AUTOSAR XML (schema 3.1.2)
package /Components/SWC_EngLimTqT
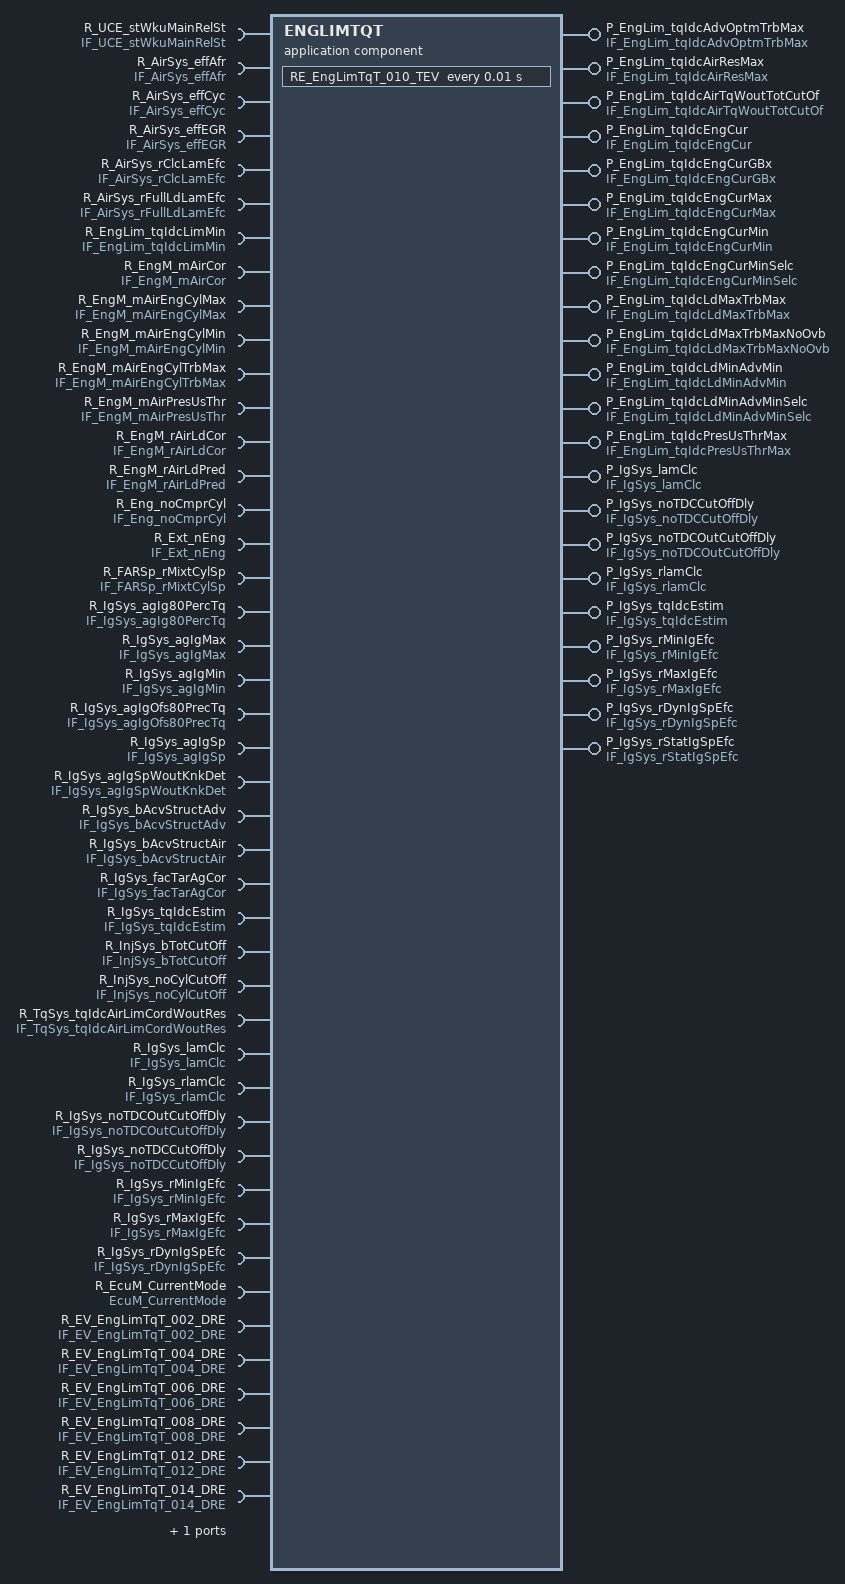
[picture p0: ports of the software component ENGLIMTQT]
  application software component type ENGLIMTQT  # EngLimTqT
    require port R_UCE_stWkuMainRelSt: required-interface=IF_UCE_stWkuMainRelSt
    22 x provide port:
      P_EngLim_tqIdcAdvOptmTrbMax: unqueued-sender-com-spec{data-element=EngLim_tqIdcAdvOptmTrbMax, can-invalidate=false, init-value=ConstantValue}, provided-interface=IF_EngLim_tqIdcAdvOptmTrbMax
      P_EngLim_tqIdcAirResMax: unqueued-sender-com-spec{data-element=EngLim_tqIdcAirResMax, can-invalidate=false, init-value=ConstantValue1}, provided-interface=IF_EngLim_tqIdcAirResMax
      P_EngLim_tqIdcAirTqWoutTotCutOf: unqueued-sender-com-spec{data-element=EngLim_tqIdcAirTqWoutTotCutOf, can-invalidate=false, init-value=ConstantValue3}, provided-interface=IF_EngLim_tqIdcAirTqWoutTotCutOf
      P_EngLim_tqIdcEngCur: unqueued-sender-com-spec{data-element=EngLim_tqIdcEngCur, can-invalidate=false, init-value=ConstantValue5}, provided-interface=IF_EngLim_tqIdcEngCur
      P_EngLim_tqIdcEngCurGBx: unqueued-sender-com-spec{data-element=EngLim_tqIdcEngCurGBx, can-invalidate=false, init-value=ConstantValue7}, provided-interface=IF_EngLim_tqIdcEngCurGBx
      P_EngLim_tqIdcEngCurMax: unqueued-sender-com-spec{data-element=EngLim_tqIdcEngCurMax, can-invalidate=false, init-value=ConstantValue9}, provided-interface=IF_EngLim_tqIdcEngCurMax
      P_EngLim_tqIdcEngCurMin: unqueued-sender-com-spec{data-element=EngLim_tqIdcEngCurMin, can-invalidate=false, init-value=ConstantValue11}, provided-interface=IF_EngLim_tqIdcEngCurMin
      P_EngLim_tqIdcEngCurMinSelc: unqueued-sender-com-spec{data-element=EngLim_tqIdcEngCurMinSelc, can-invalidate=false, init-value=ConstantValue13}, provided-interface=IF_EngLim_tqIdcEngCurMinSelc
      P_EngLim_tqIdcLdMaxTrbMax: unqueued-sender-com-spec{data-element=EngLim_tqIdcLdMaxTrbMax, can-invalidate=false, init-value=ConstantValue15}, provided-interface=IF_EngLim_tqIdcLdMaxTrbMax
      P_EngLim_tqIdcLdMaxTrbMaxNoOvb: unqueued-sender-com-spec{data-element=EngLim_tqIdcLdMaxTrbMaxNoOvb, can-invalidate=false, init-value=ConstantValue17}, provided-interface=IF_EngLim_tqIdcLdMaxTrbMaxNoOvb
      P_EngLim_tqIdcLdMinAdvMin: unqueued-sender-com-spec{data-element=EngLim_tqIdcLdMinAdvMin, can-invalidate=false, init-value=ConstantValue19}, provided-interface=IF_EngLim_tqIdcLdMinAdvMin
      P_EngLim_tqIdcLdMinAdvMinSelc: unqueued-sender-com-spec{data-element=EngLim_tqIdcLdMinAdvMinSelc, can-invalidate=false, init-value=ConstantValue21}, provided-interface=IF_EngLim_tqIdcLdMinAdvMinSelc
      P_EngLim_tqIdcPresUsThrMax: unqueued-sender-com-spec{data-element=EngLim_tqIdcPresUsThrMax, can-invalidate=false, init-value=ConstantValue23}, provided-interface=IF_EngLim_tqIdcPresUsThrMax
      P_IgSys_lamClc: unqueued-sender-com-spec{data-element=IgSys_lamClc, can-invalidate=false, init-value=UInt32InitValue}, provided-interface=IF_IgSys_lamClc
      P_IgSys_noTDCCutOffDly: unqueued-sender-com-spec{data-element=IgSys_noTDCCutOffDly, can-invalidate=false, init-value=ConstantValue25}, provided-interface=IF_IgSys_noTDCCutOffDly
      P_IgSys_noTDCOutCutOffDly: unqueued-sender-com-spec{data-element=IgSys_noTDCOutCutOffDly, can-invalidate=false, init-value=ConstantValue27}, provided-interface=IF_IgSys_noTDCOutCutOffDly
      P_IgSys_rlamClc: unqueued-sender-com-spec{data-element=IgSys_rlamClc, can-invalidate=false, init-value=ConstantValue29}, provided-interface=IF_IgSys_rlamClc
      P_IgSys_tqIdcEstim: unqueued-sender-com-spec{data-element=IgSys_tqIdcEstim, can-invalidate=false, init-value=SInt16InitValue}, provided-interface=IF_IgSys_tqIdcEstim
      P_IgSys_rMinIgEfc: unqueued-sender-com-spec{data-element=IgSys_rMinIgEfc, can-invalidate=false, init-value=UInt16InitValue}, provided-interface=IF_IgSys_rMinIgEfc
      P_IgSys_rMaxIgEfc: unqueued-sender-com-spec{data-element=IgSys_rMaxIgEfc, can-invalidate=false, init-value=UInt16InitValue31}, provided-interface=IF_IgSys_rMaxIgEfc
      P_IgSys_rDynIgSpEfc: unqueued-sender-com-spec{data-element=IgSys_rDynIgSpEfc, can-invalidate=false, init-value=UInt16InitValue33}, provided-interface=IF_IgSys_rDynIgSpEfc
      P_IgSys_rStatIgSpEfc: unqueued-sender-com-spec{data-element=IgSys_rStatIgSpEfc, can-invalidate=false, init-value=UInt16InitValue35}, provided-interface=IF_IgSys_rStatIgSpEfc
    44 x require port:
      R_AirSys_effAfr: unqueued-receiver-com-spec{data-element=AirSys_effAfr, init-value=ConstantValue37, resync-time=0}, required-interface=IF_AirSys_effAfr
      R_AirSys_effCyc: unqueued-receiver-com-spec{data-element=AirSys_effCyc, init-value=ConstantValue39, resync-time=0}, required-interface=IF_AirSys_effCyc
      R_AirSys_effEGR: unqueued-receiver-com-spec{data-element=AirSys_effEGR, init-value=ConstantValue41, resync-time=0}, required-interface=IF_AirSys_effEGR
      R_AirSys_rClcLamEfc: unqueued-receiver-com-spec{data-element=AirSys_rClcLamEfc, init-value=UInt32InitValue43, resync-time=0}, required-interface=IF_AirSys_rClcLamEfc
      R_AirSys_rFullLdLamEfc: unqueued-receiver-com-spec{data-element=AirSys_rFullLdLamEfc, init-value=UInt32InitValue45, resync-time=0}, required-interface=IF_AirSys_rFullLdLamEfc
      R_EngLim_tqIdcLimMin: unqueued-receiver-com-spec{data-element=EngLim_tqIdcLimMin, init-value=SInt16InitValue47, resync-time=0}, required-interface=IF_EngLim_tqIdcLimMin
      R_EngM_mAirCor: unqueued-receiver-com-spec{data-element=EngM_mAirCor, init-value=ConstantValue49, resync-time=0}, required-interface=IF_EngM_mAirCor
      R_EngM_mAirEngCylMax: unqueued-receiver-com-spec{data-element=EngM_mAirEngCylMax, init-value=ConstantValue51, resync-time=0}, required-interface=IF_EngM_mAirEngCylMax
      R_EngM_mAirEngCylMin: unqueued-receiver-com-spec{data-element=EngM_mAirEngCylMin, init-value=ConstantValue53, resync-time=0}, required-interface=IF_EngM_mAirEngCylMin
      R_EngM_mAirEngCylTrbMax: unqueued-receiver-com-spec{data-element=EngM_mAirEngCylTrbMax, init-value=UInt32InitValue55, resync-time=0}, required-interface=IF_EngM_mAirEngCylTrbMax
      R_EngM_mAirPresUsThr: unqueued-receiver-com-spec{data-element=EngM_mAirPresUsThr, init-value=UInt32InitValue57, resync-time=0}, required-interface=IF_EngM_mAirPresUsThr
      R_EngM_rAirLdCor: unqueued-receiver-com-spec{data-element=EngM_rAirLdCor, init-value=ConstantValue59, resync-time=0}, required-interface=IF_EngM_rAirLdCor
      R_EngM_rAirLdPred: unqueued-receiver-com-spec{data-element=EngM_rAirLdPred, init-value=ConstantValue61, resync-time=0}, required-interface=IF_EngM_rAirLdPred
      R_Eng_noCmprCyl: unqueued-receiver-com-spec{data-element=Eng_noCmprCyl, init-value=ConstantValue63, resync-time=0}, required-interface=IF_Eng_noCmprCyl
      R_Ext_nEng: unqueued-receiver-com-spec{data-element=Ext_nEng, init-value=ConstantValue65, resync-time=0}, required-interface=IF_Ext_nEng
      R_FARSp_rMixtCylSp: unqueued-receiver-com-spec{data-element=FARSp_rMixtCylSp, init-value=ConstantValue67, resync-time=0}, required-interface=IF_FARSp_rMixtCylSp
      R_IgSys_agIg80PercTq: unqueued-receiver-com-spec{data-element=IgSys_agIg80PercTq, init-value=ConstantValue69, resync-time=0}, required-interface=IF_IgSys_agIg80PercTq
      R_IgSys_agIgMax: unqueued-receiver-com-spec{data-element=IgSys_agIgMax, init-value=ConstantValue71, resync-time=0}, required-interface=IF_IgSys_agIgMax
      R_IgSys_agIgMin: unqueued-receiver-com-spec{data-element=IgSys_agIgMin, init-value=ConstantValue73, resync-time=0}, required-interface=IF_IgSys_agIgMin
      R_IgSys_agIgOfs80PrecTq: unqueued-receiver-com-spec{data-element=IgSys_agIgOfs80PrecTq, init-value=ConstantValue75, resync-time=0}, required-interface=IF_IgSys_agIgOfs80PrecTq
      R_IgSys_agIgSp: unqueued-receiver-com-spec{data-element=IgSys_agIgSp, init-value=ConstantValue77, resync-time=0}, required-interface=IF_IgSys_agIgSp
      R_IgSys_agIgSpWoutKnkDet: unqueued-receiver-com-spec{data-element=IgSys_agIgSpWoutKnkDet, init-value=ConstantValue79, resync-time=0}, required-interface=IF_IgSys_agIgSpWoutKnkDet
      R_IgSys_bAcvStructAdv: unqueued-receiver-com-spec{data-element=IgSys_bAcvStructAdv, init-value=ConstantValue81, resync-time=0}, required-interface=IF_IgSys_bAcvStructAdv
      R_IgSys_bAcvStructAir: unqueued-receiver-com-spec{data-element=IgSys_bAcvStructAir, init-value=BooleanInitValue, resync-time=0}, required-interface=IF_IgSys_bAcvStructAir
      R_IgSys_facTarAgCor: unqueued-receiver-com-spec{data-element=IgSys_facTarAgCor, init-value=ConstantValue83, resync-time=0}, required-interface=IF_IgSys_facTarAgCor
      R_IgSys_tqIdcEstim: unqueued-receiver-com-spec{data-element=IgSys_tqIdcEstim, init-value=SInt16InitValue, resync-time=0}, required-interface=IF_IgSys_tqIdcEstim
      R_InjSys_bTotCutOff: unqueued-receiver-com-spec{data-element=InjSys_bTotCutOff, init-value=BooleanInitValue85, resync-time=0}, required-interface=IF_InjSys_bTotCutOff
      R_InjSys_noCylCutOff: unqueued-receiver-com-spec{data-element=InjSys_noCylCutOff, init-value=ConstantValue87, resync-time=0}, required-interface=IF_InjSys_noCylCutOff
      R_TqSys_tqIdcAirLimCordWoutRes: unqueued-receiver-com-spec{data-element=TqSys_tqIdcAirLimCordWoutRes, init-value=ConstantValue89, resync-time=0}, required-interface=IF_TqSys_tqIdcAirLimCordWoutRes
      R_IgSys_lamClc: unqueued-receiver-com-spec{data-element=IgSys_lamClc, init-value=UInt32InitValue, resync-time=0}, required-interface=IF_IgSys_lamClc
      R_IgSys_rlamClc: unqueued-receiver-com-spec{data-element=IgSys_rlamClc, init-value=ConstantValue91, resync-time=0}, required-interface=IF_IgSys_rlamClc
      R_IgSys_noTDCOutCutOffDly: unqueued-receiver-com-spec{data-element=IgSys_noTDCOutCutOffDly, init-value=ConstantValue93, resync-time=0}, required-interface=IF_IgSys_noTDCOutCutOffDly
      R_IgSys_noTDCCutOffDly: unqueued-receiver-com-spec{data-element=IgSys_noTDCCutOffDly, init-value=ConstantValue95, resync-time=0}, required-interface=IF_IgSys_noTDCCutOffDly
      R_IgSys_rMinIgEfc: unqueued-receiver-com-spec{data-element=IgSys_rMinIgEfc, init-value=UInt16InitValue, resync-time=0}, required-interface=IF_IgSys_rMinIgEfc
      R_IgSys_rMaxIgEfc: unqueued-receiver-com-spec{data-element=IgSys_rMaxIgEfc, init-value=UInt16InitValue97, resync-time=0}, required-interface=IF_IgSys_rMaxIgEfc
      R_IgSys_rDynIgSpEfc: unqueued-receiver-com-spec{data-element=IgSys_rDynIgSpEfc, init-value=UInt16InitValue99, resync-time=0}, required-interface=IF_IgSys_rDynIgSpEfc
      R_EcuM_CurrentMode: required-interface=EcuM_CurrentMode
      R_EV_EngLimTqT_002_DRE: unqueued-receiver-com-spec{data-element=EV_EngLimTqT_002_DRE, init-value=UInt8InitValue, resync-time=0}, required-interface=IF_EV_EngLimTqT_002_DRE
      R_EV_EngLimTqT_004_DRE: unqueued-receiver-com-spec{data-element=EV_EngLimTqT_004_DRE, init-value=UInt8InitValue101, resync-time=0}, required-interface=IF_EV_EngLimTqT_004_DRE
      R_EV_EngLimTqT_006_DRE: unqueued-receiver-com-spec{data-element=EV_EngLimTqT_006_DRE, init-value=UInt8InitValue103, resync-time=0}, required-interface=IF_EV_EngLimTqT_006_DRE
      R_EV_EngLimTqT_008_DRE: unqueued-receiver-com-spec{data-element=EV_EngLimTqT_008_DRE, init-value=UInt8InitValue105, resync-time=0}, required-interface=IF_EV_EngLimTqT_008_DRE
      R_EV_EngLimTqT_012_DRE: unqueued-receiver-com-spec{data-element=EV_EngLimTqT_012_DRE, init-value=UInt8InitValue107, resync-time=0}, required-interface=IF_EV_EngLimTqT_012_DRE
      R_EV_EngLimTqT_014_DRE: unqueued-receiver-com-spec{data-element=EV_EngLimTqT_014_DRE, init-value=UInt8InitValue109, resync-time=0}, required-interface=IF_EV_EngLimTqT_014_DRE
      R_IgSys_rStatIgSpEfc: unqueued-receiver-com-spec{data-element=IgSys_rStatIgSpEfc, init-value=UInt16InitValue111, resync-time=0}, required-interface=IF_IgSys_rStatIgSpEfc
  95 x constant specification:
    BooleanInitValue
      value:
        boolean literal BooleanInitValue: type=DT_IgSys_bAcvStructAir, value=false
    BooleanInitValue85
      value:
        boolean literal BooleanInitValue85: type=DT_InjSys_bTotCutOff, value=false
    ConstantValue
      value:
        integer literal ConstantValue: type=DT_EngLim_tqIdcAdvOptmTrbMax, value=0
    ConstantValue1
      value:
        integer literal ConstantValue1: type=DT_EngLim_tqIdcAirResMax, value=0
    ConstantValue11
      value:
        integer literal ConstantValue11: type=DT_EngLim_tqIdcEngCurMin, value=0
    ConstantValue13
      value:
        integer literal ConstantValue13: type=DT_EngLim_tqIdcEngCurMinSelc, value=0
    ConstantValue15
      value:
        integer literal ConstantValue15: type=DT_EngLim_tqIdcLdMaxTrbMax, value=32000
    ConstantValue17
      value:
        integer literal ConstantValue17: type=DT_EngLim_tqIdcLdMaxTrbMaxNoOvb, value=0
    ConstantValue19
      value:
        integer literal ConstantValue19: type=DT_EngLim_tqIdcLdMinAdvMin, value=0
    ConstantValue21
      value:
        integer literal ConstantValue21: type=DT_EngLim_tqIdcLdMinAdvMinSelc, value=0
    ConstantValue23
      value:
        integer literal ConstantValue23: type=DT_EngLim_tqIdcPresUsThrMax, value=32000
    ConstantValue25
      value:
        integer literal ConstantValue25: type=DT_IgSys_noTDCCutOffDly, value=0
    ConstantValue27
      value:
        integer literal ConstantValue27: type=DT_IgSys_noTDCOutCutOffDly, value=0
    ConstantValue29
      value:
        integer literal ConstantValue29: type=DT_IgSys_rlamClc, value=1
    ConstantValue3
      value:
        integer literal ConstantValue3: type=DT_EngLim_tqIdcAirTqWoutTotCutOf, value=0
    ConstantValue37
      value:
        integer literal ConstantValue37: type=DT_AirSys_effAfr, value=0
    ConstantValue39
      value:
        integer literal ConstantValue39: type=DT_AirSys_effCyc, value=0
    ConstantValue41
      value:
        integer literal ConstantValue41: type=DT_AirSys_effEGR, value=0
    ConstantValue49
      value:
        integer literal ConstantValue49: type=DT_EngM_mAirCor, value=0
    ConstantValue5
      value:
        integer literal ConstantValue5: type=DT_EngLim_tqIdcEngCur, value=0
    ConstantValue51
      value:
        integer literal ConstantValue51: type=DT_EngM_mAirEngCylMax, value=0
    ConstantValue53
      value:
        integer literal ConstantValue53: type=DT_EngM_mAirEngCylMin, value=0
    ConstantValue59
      value:
        integer literal ConstantValue59: type=DT_EngM_rAirLdCor, value=0
    ConstantValue61
      value:
        integer literal ConstantValue61: type=DT_EngM_rAirLdPred, value=0
    ConstantValue63
      value:
        integer literal ConstantValue63: type=DT_Eng_noCmprCyl, value=1
    ConstantValue65
      value:
        integer literal ConstantValue65: type=DT_Ext_nEng, value=0
    ConstantValue67
      value:
        integer literal ConstantValue67: type=DT_FARSp_rMixtCylSp, value=4096
    ConstantValue69
      value:
        integer literal ConstantValue69: type=DT_IgSys_agIg80PercTq, value=96
    ConstantValue7
      value:
        integer literal ConstantValue7: type=DT_EngLim_tqIdcEngCurGBx, value=0
    ConstantValue71
      value:
        integer literal ConstantValue71: type=DT_IgSys_agIgMax, value=96
    ConstantValue73
      value:
        integer literal ConstantValue73: type=DT_IgSys_agIgMin, value=0
    ConstantValue75
      value:
        integer literal ConstantValue75: type=DT_IgSys_agIgOfs80PrecTq, value=96
    ConstantValue77
      value:
        integer literal ConstantValue77: type=DT_IgSys_agIgSp, value=96
    ConstantValue79
      value:
        integer literal ConstantValue79: type=DT_IgSys_agIgSpWoutKnkDet, value=192
    ConstantValue81
      value:
        boolean literal ConstantValue81: type=DT_IgSys_bAcvStructAdv, value=false
    ConstantValue83
      value:
        integer literal ConstantValue83: type=DT_IgSys_facTarAgCor, value=256
    ConstantValue87
      value:
        integer literal ConstantValue87: type=DT_InjSys_noCylCutOff, value=0
    ConstantValue89
      value:
        integer literal ConstantValue89: type=DT_TqSys_tqIdcAirLimCordWoutRes, value=0
    ConstantValue9
      value:
        integer literal ConstantValue9: type=DT_EngLim_tqIdcEngCurMax, value=32000
    ConstantValue91
      value:
        integer literal ConstantValue91: type=DT_IgSys_rlamClc, value=1
    ConstantValue93
      value:
        integer literal ConstantValue93: type=DT_IgSys_noTDCOutCutOffDly, value=0
    ConstantValue95
      value:
        integer literal ConstantValue95: type=DT_IgSys_noTDCCutOffDly, value=0
    InitValue_Boolean_0
      value:
        boolean literal InitValue_Boolean_0: type=DT_IgSys_bTqIdcCutOff_irv, value=false
    InitValue_SInt16_0
      value:
        integer literal InitValue_SInt16_0: type=DT_IgSys_tqIdcEstimAvgCylWoutLa_irv, value=0
    InitValue_SInt16_0121
      value:
        integer literal InitValue_SInt16_0121: type=DT_EngLim_tqIdcAdvOptmMaxWoutOf_irv, value=0
    InitValue_SInt16_0135
      value:
        integer literal InitValue_SInt16_0135: type=DT_EngLim_tqIdcPresUsMax_irv, value=0
    InitValue_SInt16_0143
      value:
        integer literal InitValue_SInt16_0143: type=DT_EngLim_tqIdcMinAirLdAvgCyl_irv, value=0
    InitValue_SInt16_0145
      value:
        integer literal InitValue_SInt16_0145: type=DT_IgSys_tqIdcEstimAvgCyl_irv, value=0
    InitValue_SInt16_0157
      value:
        integer literal InitValue_SInt16_0157: type=DT_EngLim_tqIdcMinAirLd_irv, value=0
    InitValue_SInt16_0159
      value:
        integer literal InitValue_SInt16_0159: type=DT_IgSys_tqIdcEstimAvgCylWiLam_irv, value=0
    InitValue_SInt16_0161
      value:
        integer literal InitValue_SInt16_0161: type=DT_EngLim_tqIdcTrbMaxWoutOvb_irv, value=0
    InitValue_UInt16_0
      value:
        integer literal InitValue_UInt16_0: type=DT_IgSys_prm_rStatIgSpEfcCyl_04_irv, value=0
    InitValue_UInt16_0113
      value:
        integer literal InitValue_UInt16_0113: type=DT_IgSys_prm_rMaxIgSpEfcCyl_05_irv, value=0
    InitValue_UInt16_0115
      value:
        integer literal InitValue_UInt16_0115: type=DT_IgSys_prm_rStatIgSpEfcCyl_02_irv, value=0
    InitValue_UInt16_0117
      value:
        integer literal InitValue_UInt16_0117: type=DT_IgSys_prm_rDynIgSpEfcCyl_05_irv, value=0
    InitValue_UInt16_0119
      value:
        integer literal InitValue_UInt16_0119: type=DT_IgSys_prm_rDynIgSpEfcCyl_06_irv, value=0
    InitValue_UInt16_0123
      value:
        integer literal InitValue_UInt16_0123: type=DT_IgSys_prm_rStatIgSpEfcCyl_01_irv, value=0
    InitValue_UInt16_0125
      value:
        integer literal InitValue_UInt16_0125: type=DT_IgSys_prm_rMaxIgSpEfcCyl_01_irv, value=0
    InitValue_UInt16_0127
      value:
        integer literal InitValue_UInt16_0127: type=DT_IgSys_prm_rStatIgSpEfcCyl_03_irv, value=0
    InitValue_UInt16_0131
      value:
        integer literal InitValue_UInt16_0131: type=DT_IgSys_prm_rDynIgSpEfcCyl_02_irv, value=0
    InitValue_UInt16_0133
      value:
        integer literal InitValue_UInt16_0133: type=DT_IgSys_prm_rMaxIgSpEfcCyl_02_irv, value=0
    InitValue_UInt16_0137
      value:
        integer literal InitValue_UInt16_0137: type=DT_IgSys_prm_rDynIgSpEfcCyl_03_irv, value=0
    InitValue_UInt16_0139
      value:
        integer literal InitValue_UInt16_0139: type=DT_IgSys_prm_rMaxIgSpEfcCyl_03_irv, value=0
    InitValue_UInt16_0141
      value:
        integer literal InitValue_UInt16_0141: type=DT_IgSys_prm_rDynIgSpEfcCyl_01_irv, value=0
    InitValue_UInt16_0147
      value:
        integer literal InitValue_UInt16_0147: type=DT_IgSys_prm_rMaxIgSpEfcCyl_06_irv, value=0
    InitValue_UInt16_0149
      value:
        integer literal InitValue_UInt16_0149: type=DT_IgSys_rStatIgSpEfcWoutMv_irv, value=0
    InitValue_UInt16_0151
      value:
        integer literal InitValue_UInt16_0151: type=DT_IgSys_prm_rStatIgSpEfcCyl_06_irv, value=0
    InitValue_UInt16_0153
      value:
        integer literal InitValue_UInt16_0153: type=DT_IgSys_prm_rMaxIgSpEfcCyl_04_irv, value=0
    InitValue_UInt16_0155
      value:
        integer literal InitValue_UInt16_0155: type=DT_IgSys_prm_rStatIgSpEfcCyl_05_irv, value=0
    InitValue_UInt16_0163
      value:
        integer literal InitValue_UInt16_0163: type=DT_IgSys_rDynIgSpEfcWoutMv_irv, value=0
    InitValue_UInt16_0165
      value:
        integer literal InitValue_UInt16_0165: type=DT_IgSys_rAirLdPred_irv, value=0
    InitValue_UInt16_0167
      value:
        integer literal InitValue_UInt16_0167: type=DT_IgSys_prm_rDynIgSpEfcCyl_04_irv, value=0
    InitValue_UInt32_0
      value:
        integer literal InitValue_UInt32_0: type=DT_IgSys_rlamEngCorReq_irv, value=0
    InitValue_UInt8_0
      value:
        integer literal InitValue_UInt8_0: type=DT_IgSys_noCylInc1_irv, value=0
    InitValue_UInt8_0129
      value:
        integer literal InitValue_UInt8_0129: type=DT_IgSys_noCylCutOffDlyOutSat_irv, value=0
    SInt16InitValue
      value:
        integer literal SInt16InitValue: type=DT_IgSys_tqIdcEstim, value=0
    SInt16InitValue47
      value:
        integer literal SInt16InitValue47: type=DT_EngLim_tqIdcLimMin, value=32000
    UInt16InitValue
      value:
        integer literal UInt16InitValue: type=DT_IgSys_rMinIgEfc, value=0
    UInt16InitValue111
      value:
        integer literal UInt16InitValue111: type=DT_IgSys_rStatIgSpEfc, value=0
    UInt16InitValue31
      value:
        integer literal UInt16InitValue31: type=DT_IgSys_rMaxIgEfc, value=0
    UInt16InitValue33
      value:
        integer literal UInt16InitValue33: type=DT_IgSys_rDynIgSpEfc, value=0
    UInt16InitValue35
      value:
        integer literal UInt16InitValue35: type=DT_IgSys_rStatIgSpEfc, value=0
    UInt16InitValue97
      value:
        integer literal UInt16InitValue97: type=DT_IgSys_rMaxIgEfc, value=0
    UInt16InitValue99
      value:
        integer literal UInt16InitValue99: type=DT_IgSys_rDynIgSpEfc, value=0
    UInt32InitValue
      value:
        integer literal UInt32InitValue: type=DT_IgSys_lamClc, value=0
    UInt32InitValue43
      value:
        integer literal UInt32InitValue43: type=DT_AirSys_rClcLamEfc, value=0
    UInt32InitValue45
      value:
        integer literal UInt32InitValue45: type=DT_AirSys_rFullLdLamEfc, value=0
    UInt32InitValue55
      value:
        integer literal UInt32InitValue55: type=DT_EngM_mAirEngCylTrbMax, value=0
    UInt32InitValue57
      value:
        integer literal UInt32InitValue57: type=DT_EngM_mAirPresUsThr, value=0
    UInt8InitValue
      value:
        integer literal UInt8InitValue: type=DT_EV_EngLimTqT_002_DRE, value=0
    UInt8InitValue101
      value:
        integer literal UInt8InitValue101: type=DT_EV_EngLimTqT_004_DRE, value=0
    UInt8InitValue103
      value:
        integer literal UInt8InitValue103: type=DT_EV_EngLimTqT_006_DRE, value=0
    UInt8InitValue105
      value:
        integer literal UInt8InitValue105: type=DT_EV_EngLimTqT_008_DRE, value=0
    UInt8InitValue107
      value:
        integer literal UInt8InitValue107: type=DT_EV_EngLimTqT_012_DRE, value=0
    UInt8InitValue109
      value:
        integer literal UInt8InitValue109: type=DT_EV_EngLimTqT_014_DRE, value=0
  internal behavior IB_EngLimTqT: component=ENGLIMTQT
    mode switch event EV_EngLimTqT_007_MSE: start-on-event=RE_EngLimTqT_007_MSE, activation=ENTRY, mode=R_EcuM_CurrentMode.currentMode.RUN
    data received event EV_EngLimTqT_006_DRE: mode-dependency=dependent-on-mode=[R_UCE_stWkuMainRelSt.RCD_stWkuMainRelSt.PreMainWakeUp, R_UCE_stWkuMainRelSt.RCD_stWkuMainRelSt.PostMainWakeUp, R_UCE_stWkuMainRelSt.RCD_stWkuMainRelSt.Invalid], start-on-event=RE_EngLimTqT_006_DRE, data=R_EV_EngLimTqT_006_DRE.EV_EngLimTqT_006_DRE
    data received event EV_EngLimTqT_004_DRE: mode-dependency=dependent-on-mode=[R_UCE_stWkuMainRelSt.RCD_stWkuMainRelSt.PreMainWakeUp, R_UCE_stWkuMainRelSt.RCD_stWkuMainRelSt.PostMainWakeUp, R_UCE_stWkuMainRelSt.RCD_stWkuMainRelSt.Invalid], start-on-event=RE_EngLimTqT_004_DRE, data=R_EV_EngLimTqT_004_DRE.EV_EngLimTqT_004_DRE
    mode switch event EV_EngLimTqT_013_MSE: start-on-event=RE_EngLimTqT_013_MSE, activation=ENTRY, mode=R_EcuM_CurrentMode.currentMode.RUN
    mode switch event EV_EngLimTqT_001_MSE: start-on-event=RE_EngLimTqT_001_MSE, activation=ENTRY, mode=R_EcuM_CurrentMode.currentMode.RUN
    data received event EV_EngLimTqT_002_DRE: mode-dependency=dependent-on-mode=[R_UCE_stWkuMainRelSt.RCD_stWkuMainRelSt.PreMainWakeUp, R_UCE_stWkuMainRelSt.RCD_stWkuMainRelSt.PostMainWakeUp, R_UCE_stWkuMainRelSt.RCD_stWkuMainRelSt.Invalid], start-on-event=RE_EngLimTqT_002_DRE, data=R_EV_EngLimTqT_002_DRE.EV_EngLimTqT_002_DRE
    data received event EV_EngLimTqT_014_DRE: mode-dependency=dependent-on-mode=[R_UCE_stWkuMainRelSt.RCD_stWkuMainRelSt.PreMainWakeUp, R_UCE_stWkuMainRelSt.RCD_stWkuMainRelSt.PostMainWakeUp, R_UCE_stWkuMainRelSt.RCD_stWkuMainRelSt.Invalid], start-on-event=RE_EngLimTqT_014_DRE, data=R_EV_EngLimTqT_014_DRE.EV_EngLimTqT_014_DRE
    data received event EV_EngLimTqT_008_DRE: mode-dependency=dependent-on-mode=[R_UCE_stWkuMainRelSt.RCD_stWkuMainRelSt.PreMainWakeUp, R_UCE_stWkuMainRelSt.RCD_stWkuMainRelSt.PostMainWakeUp, R_UCE_stWkuMainRelSt.RCD_stWkuMainRelSt.Invalid], start-on-event=RE_EngLimTqT_008_DRE, data=R_EV_EngLimTqT_008_DRE.EV_EngLimTqT_008_DRE
    mode switch event EV_EngLimTqT_003_MSE: start-on-event=RE_EngLimTqT_003_MSE, activation=ENTRY, mode=R_EcuM_CurrentMode.currentMode.RUN
    timing event EV_EngLimTqT_010_TEV: mode-dependency=dependent-on-mode=[R_UCE_stWkuMainRelSt.RCD_stWkuMainRelSt.PreMainWakeUp, R_UCE_stWkuMainRelSt.RCD_stWkuMainRelSt.PostMainWakeUp, R_UCE_stWkuMainRelSt.RCD_stWkuMainRelSt.Invalid], start-on-event=RE_EngLimTqT_010_TEV, period=0.01
    mode switch event EV_EngLimTqT_009_MSE: start-on-event=RE_EngLimTqT_009_MSE, activation=ENTRY, mode=R_EcuM_CurrentMode.currentMode.RUN
    mode switch event EV_EngLimTqT_011_MSE: start-on-event=RE_EngLimTqT_011_MSE, activation=ENTRY, mode=R_EcuM_CurrentMode.currentMode.RUN
    data received event EV_EngLimTqT_012_DRE: mode-dependency=dependent-on-mode=[R_UCE_stWkuMainRelSt.RCD_stWkuMainRelSt.PreMainWakeUp, R_UCE_stWkuMainRelSt.RCD_stWkuMainRelSt.PostMainWakeUp, R_UCE_stWkuMainRelSt.RCD_stWkuMainRelSt.Invalid], start-on-event=RE_EngLimTqT_012_DRE, data=R_EV_EngLimTqT_012_DRE.EV_EngLimTqT_012_DRE
    mode switch event EV_EngLimTqT_005_MSE: start-on-event=RE_EngLimTqT_005_MSE, activation=ENTRY, mode=R_EcuM_CurrentMode.currentMode.RUN
    33 x inter runnable variable, all with sw-calibration-access=READ-WRITE, communication-approach=EXPLICIT:
      IgSys_noCylInc1_irv: type=DT_IgSys_noCylInc1_irv, init-value=InitValue_UInt8_0
      IgSys_prm_rMaxIgSpEfcCyl_01_irv: type=DT_IgSys_prm_rMaxIgSpEfcCyl_01_irv, init-value=InitValue_UInt16_0125
      IgSys_prm_rDynIgSpEfcCyl_04_irv: type=DT_IgSys_prm_rDynIgSpEfcCyl_04_irv, init-value=InitValue_UInt16_0167
      EngLim_tqIdcAdvOptmMaxWoutOf_irv: type=DT_EngLim_tqIdcAdvOptmMaxWoutOf_irv, init-value=InitValue_SInt16_0121
      IgSys_prm_rMaxIgSpEfcCyl_03_irv: type=DT_IgSys_prm_rMaxIgSpEfcCyl_03_irv, init-value=InitValue_UInt16_0139
      IgSys_prm_rDynIgSpEfcCyl_06_irv: type=DT_IgSys_prm_rDynIgSpEfcCyl_06_irv, init-value=InitValue_UInt16_0119
      IgSys_prm_rStatIgSpEfcCyl_03_irv: type=DT_IgSys_prm_rStatIgSpEfcCyl_03_irv, init-value=InitValue_UInt16_0127
      EngLim_tqIdcPresUsMax_irv: type=DT_EngLim_tqIdcPresUsMax_irv, init-value=InitValue_SInt16_0135
      IgSys_rAirLdPred_irv: type=DT_IgSys_rAirLdPred_irv, init-value=InitValue_UInt16_0165
      IgSys_tqIdcEstimAvgCylWiLam_irv: type=DT_IgSys_tqIdcEstimAvgCylWiLam_irv, init-value=InitValue_SInt16_0159
      EngLim_tqIdcMinAirLdAvgCyl_irv: type=DT_EngLim_tqIdcMinAirLdAvgCyl_irv, init-value=InitValue_SInt16_0143
      IgSys_rDynIgSpEfcWoutMv_irv: type=DT_IgSys_rDynIgSpEfcWoutMv_irv, init-value=InitValue_UInt16_0163
      IgSys_rlamEngCorReq_irv: type=DT_IgSys_rlamEngCorReq_irv, init-value=InitValue_UInt32_0
      IgSys_prm_rDynIgSpEfcCyl_05_irv: type=DT_IgSys_prm_rDynIgSpEfcCyl_05_irv, init-value=InitValue_UInt16_0117
      IgSys_bTqIdcCutOff_irv: type=DT_IgSys_bTqIdcCutOff_irv, init-value=InitValue_Boolean_0
      IgSys_prm_rMaxIgSpEfcCyl_04_irv: type=DT_IgSys_prm_rMaxIgSpEfcCyl_04_irv, init-value=InitValue_UInt16_0153
      IgSys_rStatIgSpEfcWoutMv_irv: type=DT_IgSys_rStatIgSpEfcWoutMv_irv, init-value=InitValue_UInt16_0149
      IgSys_prm_rDynIgSpEfcCyl_02_irv: type=DT_IgSys_prm_rDynIgSpEfcCyl_02_irv, init-value=InitValue_UInt16_0131
      EngLim_tqIdcMinAirLd_irv: type=DT_EngLim_tqIdcMinAirLd_irv, init-value=InitValue_SInt16_0157
      IgSys_prm_rStatIgSpEfcCyl_02_irv: type=DT_IgSys_prm_rStatIgSpEfcCyl_02_irv, init-value=InitValue_UInt16_0115
      IgSys_prm_rMaxIgSpEfcCyl_06_irv: type=DT_IgSys_prm_rMaxIgSpEfcCyl_06_irv, init-value=InitValue_UInt16_0147
      IgSys_prm_rMaxIgSpEfcCyl_05_irv: type=DT_IgSys_prm_rMaxIgSpEfcCyl_05_irv, init-value=InitValue_UInt16_0113
      EngLim_tqIdcTrbMaxWoutOvb_irv: type=DT_EngLim_tqIdcTrbMaxWoutOvb_irv, init-value=InitValue_SInt16_0161
      IgSys_prm_rStatIgSpEfcCyl_06_irv: type=DT_IgSys_prm_rStatIgSpEfcCyl_06_irv, init-value=InitValue_UInt16_0151
      IgSys_prm_rDynIgSpEfcCyl_03_irv: type=DT_IgSys_prm_rDynIgSpEfcCyl_03_irv, init-value=InitValue_UInt16_0137
      IgSys_noCylCutOffDlyOutSat_irv: type=DT_IgSys_noCylCutOffDlyOutSat_irv, init-value=InitValue_UInt8_0129
      IgSys_prm_rMaxIgSpEfcCyl_02_irv: type=DT_IgSys_prm_rMaxIgSpEfcCyl_02_irv, init-value=InitValue_UInt16_0133
      IgSys_prm_rStatIgSpEfcCyl_04_irv: type=DT_IgSys_prm_rStatIgSpEfcCyl_04_irv, init-value=InitValue_UInt16_0
      IgSys_prm_rStatIgSpEfcCyl_01_irv: type=DT_IgSys_prm_rStatIgSpEfcCyl_01_irv, init-value=InitValue_UInt16_0123
      IgSys_prm_rDynIgSpEfcCyl_01_irv: type=DT_IgSys_prm_rDynIgSpEfcCyl_01_irv, init-value=InitValue_UInt16_0141
      IgSys_tqIdcEstimAvgCyl_irv: type=DT_IgSys_tqIdcEstimAvgCyl_irv, init-value=InitValue_SInt16_0145
      IgSys_tqIdcEstimAvgCylWoutLa_irv: type=DT_IgSys_tqIdcEstimAvgCylWoutLa_irv, init-value=InitValue_SInt16_0
      IgSys_prm_rStatIgSpEfcCyl_05_irv: type=DT_IgSys_prm_rStatIgSpEfcCyl_05_irv, init-value=InitValue_UInt16_0155
    14 x runnable:
      RE_EngLimTqT_012_DRE: read-variable=[IgSys_noCylInc1_irv, IgSys_prm_rMaxIgSpEfcCyl_05_irv, IgSys_prm_rMaxIgSpEfcCyl_01_irv, IgSys_prm_rMaxIgSpEfcCyl_02_irv, IgSys_prm_rMaxIgSpEfcCyl_04_irv, IgSys_prm_rMaxIgSpEfcCyl_06_irv, IgSys_prm_rMaxIgSpEfcCyl_03_irv], written-variable=[IgSys_noCylInc1_irv, IgSys_prm_rMaxIgSpEfcCyl_05_irv, IgSys_prm_rMaxIgSpEfcCyl_01_irv, IgSys_prm_rMaxIgSpEfcCyl_02_irv, IgSys_prm_rMaxIgSpEfcCyl_04_irv, IgSys_prm_rMaxIgSpEfcCyl_06_irv, IgSys_prm_rMaxIgSpEfcCyl_03_irv]
        10 x data receive point:
          dr_IgSys_rMaxIgEfc: data-element=R_IgSys_rMaxIgEfc.IgSys_rMaxIgEfc
          dr_IgSys_agIgOfs80PrecTq: data-element=R_IgSys_agIgOfs80PrecTq.IgSys_agIgOfs80PrecTq
          dr_IgSys_bAcvStructAdv: data-element=R_IgSys_bAcvStructAdv.IgSys_bAcvStructAdv
          dr_IgSys_agIgMax: data-element=R_IgSys_agIgMax.IgSys_agIgMax
          dr_IgSys_facTarAgCor: data-element=R_IgSys_facTarAgCor.IgSys_facTarAgCor
          dr_IgSys_agIg80PercTq: data-element=R_IgSys_agIg80PercTq.IgSys_agIg80PercTq
          dr_Eng_noCmprCyl: data-element=R_Eng_noCmprCyl.Eng_noCmprCyl
          dr_IgSys_agIgMin: data-element=R_IgSys_agIgMin.IgSys_agIgMin
          dr_EV_EngLimTqT_012_DRE: data-element=R_EV_EngLimTqT_012_DRE.EV_EngLimTqT_012_DRE
          dr_IgSys_rMinIgEfc: data-element=R_IgSys_rMinIgEfc.IgSys_rMinIgEfc
        data send point ds_IgSys_rMaxIgEfc: data-element=P_IgSys_rMaxIgEfc.IgSys_rMaxIgEfc
        data send point ds_IgSys_rMinIgEfc: data-element=P_IgSys_rMinIgEfc.IgSys_rMinIgEfc
      RE_EngLimTqT_009_MSE: written-variable=[IgSys_rAirLdPred_irv, IgSys_rlamEngCorReq_irv]
        data send point ds_IgSys_lamClc: data-element=P_IgSys_lamClc.IgSys_lamClc
        data send point ds_IgSys_rlamClc: data-element=P_IgSys_rlamClc.IgSys_rlamClc
      RE_EngLimTqT_007_MSE
        data send point ds_EngLim_tqIdcEngCurGBx: data-element=P_EngLim_tqIdcEngCurGBx.EngLim_tqIdcEngCurGBx
        data send point ds_EngLim_tqIdcEngCur: data-element=P_EngLim_tqIdcEngCur.EngLim_tqIdcEngCur
      RE_EngLimTqT_002_DRE: read-variable=[IgSys_bTqIdcCutOff_irv, IgSys_noCylCutOffDlyOutSat_irv], written-variable=[IgSys_bTqIdcCutOff_irv, IgSys_noCylCutOffDlyOutSat_irv]
        7 x data receive point:
          dr_InjSys_bTotCutOff: data-element=R_InjSys_bTotCutOff.InjSys_bTotCutOff
          DRP_R_IgSys_noTDCOutCutOffDly_IgSys_noTDCOutCutOffDly: data-element=R_IgSys_noTDCOutCutOffDly.IgSys_noTDCOutCutOffDly
          dr_InjSys_noCylCutOff: data-element=R_InjSys_noCylCutOff.InjSys_noCylCutOff
          dr_IgSys_noTDCCutOffDly: data-element=R_IgSys_noTDCCutOffDly.IgSys_noTDCCutOffDly
          dr_IgSys_bAcvStructAir: data-element=R_IgSys_bAcvStructAir.IgSys_bAcvStructAir
          dr_EV_EngLimTqT_002_DRE: data-element=R_EV_EngLimTqT_002_DRE.EV_EngLimTqT_002_DRE
          dr_Ext_nEng: data-element=R_Ext_nEng.Ext_nEng
        data send point ds_IgSys_noTDCOutCutOffDly: data-element=P_IgSys_noTDCOutCutOffDly.IgSys_noTDCOutCutOffDly
      RE_EngLimTqT_001_MSE: written-variable=[IgSys_noCylCutOffDlyOutSat_irv, IgSys_bTqIdcCutOff_irv]
        data send point ds_IgSys_noTDCCutOffDly: data-element=P_IgSys_noTDCCutOffDly.IgSys_noTDCCutOffDly
        data send point ds_IgSys_noTDCOutCutOffDly: data-element=P_IgSys_noTDCOutCutOffDly.IgSys_noTDCOutCutOffDly
      RE_EngLimTqT_011_MSE: written-variable=[IgSys_noCylInc1_irv, IgSys_prm_rMaxIgSpEfcCyl_02_irv, IgSys_prm_rMaxIgSpEfcCyl_04_irv, IgSys_prm_rMaxIgSpEfcCyl_01_irv, IgSys_prm_rMaxIgSpEfcCyl_06_irv, IgSys_prm_rMaxIgSpEfcCyl_03_irv, IgSys_prm_rMaxIgSpEfcCyl_05_irv]
        data send point ds_IgSys_rMaxIgEfc: data-element=P_IgSys_rMaxIgEfc.IgSys_rMaxIgEfc
        data send point ds_IgSys_rMinIgEfc: data-element=P_IgSys_rMinIgEfc.IgSys_rMinIgEfc
      RE_EngLimTqT_014_DRE: read-variable=[IgSys_prm_rStatIgSpEfcCyl_06_irv, IgSys_prm_rDynIgSpEfcCyl_02_irv, IgSys_prm_rDynIgSpEfcCyl_01_irv, IgSys_prm_rStatIgSpEfcCyl_04_irv, IgSys_prm_rDynIgSpEfcCyl_03_irv, IgSys_prm_rStatIgSpEfcCyl_03_irv, IgSys_rStatIgSpEfcWoutMv_irv, IgSys_rDynIgSpEfcWoutMv_irv, IgSys_prm_rStatIgSpEfcCyl_05_irv, IgSys_prm_rDynIgSpEfcCyl_05_irv, IgSys_noCylInc1_irv, IgSys_prm_rDynIgSpEfcCyl_06_irv, IgSys_prm_rDynIgSpEfcCyl_04_irv, IgSys_prm_rStatIgSpEfcCyl_02_irv, IgSys_prm_rStatIgSpEfcCyl_01_irv], written-variable=[IgSys_prm_rStatIgSpEfcCyl_06_irv, IgSys_prm_rDynIgSpEfcCyl_02_irv, IgSys_prm_rDynIgSpEfcCyl_01_irv, IgSys_prm_rStatIgSpEfcCyl_04_irv, IgSys_prm_rDynIgSpEfcCyl_03_irv, IgSys_prm_rStatIgSpEfcCyl_03_irv, IgSys_rStatIgSpEfcWoutMv_irv, IgSys_rDynIgSpEfcWoutMv_irv, IgSys_prm_rStatIgSpEfcCyl_05_irv, IgSys_prm_rDynIgSpEfcCyl_05_irv, IgSys_prm_rDynIgSpEfcCyl_06_irv, IgSys_prm_rDynIgSpEfcCyl_04_irv, IgSys_prm_rStatIgSpEfcCyl_02_irv, IgSys_prm_rStatIgSpEfcCyl_01_irv]
        10 x data receive point:
          dr_Eng_noCmprCyl: data-element=R_Eng_noCmprCyl.Eng_noCmprCyl
          dr_IgSys_rDynIgSpEfc: data-element=R_IgSys_rDynIgSpEfc.IgSys_rDynIgSpEfc
          dr_IgSys_agIg80PercTq: data-element=R_IgSys_agIg80PercTq.IgSys_agIg80PercTq
          dr_IgSys_facTarAgCor: data-element=R_IgSys_facTarAgCor.IgSys_facTarAgCor
          dr_IgSys_bAcvStructAdv: data-element=R_IgSys_bAcvStructAdv.IgSys_bAcvStructAdv
          dr_EV_EngLimTqT_014_DRE: data-element=R_EV_EngLimTqT_014_DRE.EV_EngLimTqT_014_DRE
          dr_IgSys_rStatIgSpEfc: data-element=R_IgSys_rStatIgSpEfc.IgSys_rStatIgSpEfc
          dr_IgSys_agIgSp: data-element=R_IgSys_agIgSp.IgSys_agIgSp
          dr_IgSys_agIgSpWoutKnkDet: data-element=R_IgSys_agIgSpWoutKnkDet.IgSys_agIgSpWoutKnkDet
          dr_IgSys_agIgOfs80PrecTq: data-element=R_IgSys_agIgOfs80PrecTq.IgSys_agIgOfs80PrecTq
        data send point ds_IgSys_rStatIgSpEfc: data-element=P_IgSys_rStatIgSpEfc.IgSys_rStatIgSpEfc
        data send point ds_IgSys_rDynIgSpEfc: data-element=P_IgSys_rDynIgSpEfc.IgSys_rDynIgSpEfc
      RE_EngLimTqT_003_MSE: written-variable=[EngLim_tqIdcPresUsMax_irv, IgSys_tqIdcEstimAvgCylWiLam_irv, IgSys_tqIdcEstimAvgCylWoutLa_irv, IgSys_tqIdcEstimAvgCyl_irv, EngLim_tqIdcMinAirLdAvgCyl_irv, EngLim_tqIdcTrbMaxWoutOvb_irv, EngLim_tqIdcAdvOptmMaxWoutOf_irv, EngLim_tqIdcMinAirLd_irv]
        data send point ds_EngLim_tqIdcAirTqWoutTotCutOf: data-element=P_EngLim_tqIdcAirTqWoutTotCutOf.EngLim_tqIdcAirTqWoutTotCutOf
        data send point ds_EngLim_tqIdcAdvOptmTrbMax: data-element=P_EngLim_tqIdcAdvOptmTrbMax.EngLim_tqIdcAdvOptmTrbMax
        data send point ds_IgSys_tqIdcEstim: data-element=P_IgSys_tqIdcEstim.IgSys_tqIdcEstim
      RE_EngLimTqT_008_DRE: read-variable=[IgSys_rStatIgSpEfcWoutMv_irv, IgSys_rDynIgSpEfcWoutMv_irv, IgSys_bTqIdcCutOff_irv, IgSys_tqIdcEstimAvgCylWoutLa_irv, IgSys_tqIdcEstimAvgCylWiLam_irv]
        4 x data receive point:
          dr_IgSys_rStatIgSpEfc: data-element=R_IgSys_rStatIgSpEfc.IgSys_rStatIgSpEfc
          dr_EV_EngLimTqT_008_DRE: data-element=R_EV_EngLimTqT_008_DRE.EV_EngLimTqT_008_DRE
          dr_IgSys_bAcvStructAdv: data-element=R_IgSys_bAcvStructAdv.IgSys_bAcvStructAdv
          dr_IgSys_rDynIgSpEfc: data-element=R_IgSys_rDynIgSpEfc.IgSys_rDynIgSpEfc
        data send point ds_EngLim_tqIdcEngCurGBx: data-element=P_EngLim_tqIdcEngCurGBx.EngLim_tqIdcEngCurGBx
        data send point ds_EngLim_tqIdcEngCur: data-element=P_EngLim_tqIdcEngCur.EngLim_tqIdcEngCur
      RE_EngLimTqT_013_MSE: written-variable=[IgSys_rStatIgSpEfcWoutMv_irv, IgSys_prm_rStatIgSpEfcCyl_05_irv, IgSys_prm_rDynIgSpEfcCyl_03_irv, IgSys_prm_rStatIgSpEfcCyl_01_irv, IgSys_prm_rDynIgSpEfcCyl_02_irv, IgSys_prm_rDynIgSpEfcCyl_06_irv, IgSys_rDynIgSpEfcWoutMv_irv, IgSys_prm_rStatIgSpEfcCyl_06_irv, IgSys_prm_rDynIgSpEfcCyl_01_irv, IgSys_prm_rStatIgSpEfcCyl_03_irv, IgSys_prm_rDynIgSpEfcCyl_05_irv, IgSys_prm_rStatIgSpEfcCyl_02_irv, IgSys_prm_rDynIgSpEfcCyl_04_irv, IgSys_prm_rStatIgSpEfcCyl_04_irv]
        data send point ds_IgSys_rStatIgSpEfc: data-element=P_IgSys_rStatIgSpEfc.IgSys_rStatIgSpEfc
        data send point ds_IgSys_rDynIgSpEfc: data-element=P_IgSys_rDynIgSpEfc.IgSys_rDynIgSpEfc
      RE_EngLimTqT_006_DRE: read-variable=[EngLim_tqIdcAdvOptmMaxWoutOf_irv, IgSys_bTqIdcCutOff_irv, EngLim_tqIdcTrbMaxWoutOvb_irv, EngLim_tqIdcMinAirLdAvgCyl_irv, EngLim_tqIdcPresUsMax_irv, EngLim_tqIdcMinAirLd_irv, IgSys_tqIdcEstimAvgCyl_irv]
        7 x data receive point:
          dr_IgSys_rMaxIgEfc: data-element=R_IgSys_rMaxIgEfc.IgSys_rMaxIgEfc
          dr_IgSys_bAcvStructAdv: data-element=R_IgSys_bAcvStructAdv.IgSys_bAcvStructAdv
          dr_EV_EngLimTqT_006_DRE: data-element=R_EV_EngLimTqT_006_DRE.EV_EngLimTqT_006_DRE
          dr_Ext_nEng: data-element=R_Ext_nEng.Ext_nEng
          dr_IgSys_rMinIgEfc: data-element=R_IgSys_rMinIgEfc.IgSys_rMinIgEfc
          dr_TqSys_tqIdcAirLimCordWoutRes: data-element=R_TqSys_tqIdcAirLimCordWoutRes.TqSys_tqIdcAirLimCordWoutRes
          dr_IgSys_tqIdcEstim: data-element=R_IgSys_tqIdcEstim.IgSys_tqIdcEstim
        9 x data send point:
          ds_EngLim_tqIdcEngCurMax: data-element=P_EngLim_tqIdcEngCurMax.EngLim_tqIdcEngCurMax
          ds_EngLim_tqIdcLdMaxTrbMax: data-element=P_EngLim_tqIdcLdMaxTrbMax.EngLim_tqIdcLdMaxTrbMax
          ds_EngLim_tqIdcLdMinAdvMinSelc: data-element=P_EngLim_tqIdcLdMinAdvMinSelc.EngLim_tqIdcLdMinAdvMinSelc
          ds_EngLim_tqIdcPresUsThrMax: data-element=P_EngLim_tqIdcPresUsThrMax.EngLim_tqIdcPresUsThrMax
          ds_EngLim_tqIdcEngCurMinSelc: data-element=P_EngLim_tqIdcEngCurMinSelc.EngLim_tqIdcEngCurMinSelc
          ds_EngLim_tqIdcAirResMax: data-element=P_EngLim_tqIdcAirResMax.EngLim_tqIdcAirResMax
          ds_EngLim_tqIdcLdMinAdvMin: data-element=P_EngLim_tqIdcLdMinAdvMin.EngLim_tqIdcLdMinAdvMin
          ds_EngLim_tqIdcLdMaxTrbMaxNoOvb: data-element=P_EngLim_tqIdcLdMaxTrbMaxNoOvb.EngLim_tqIdcLdMaxTrbMaxNoOvb
          ds_EngLim_tqIdcEngCurMin: data-element=P_EngLim_tqIdcEngCurMin.EngLim_tqIdcEngCurMin
      RE_EngLimTqT_005_MSE
        10 x data send point:
          ds_IgSys_noTDCOutCutOffDly: data-element=P_IgSys_noTDCOutCutOffDly.IgSys_noTDCOutCutOffDly
          ds_EngLim_tqIdcLdMaxTrbMax: data-element=P_EngLim_tqIdcLdMaxTrbMax.EngLim_tqIdcLdMaxTrbMax
          ds_EngLim_tqIdcLdMinAdvMinSelc: data-element=P_EngLim_tqIdcLdMinAdvMinSelc.EngLim_tqIdcLdMinAdvMinSelc
          ds_EngLim_tqIdcAirResMax: data-element=P_EngLim_tqIdcAirResMax.EngLim_tqIdcAirResMax
          ds_EngLim_tqIdcEngCurMax: data-element=P_EngLim_tqIdcEngCurMax.EngLim_tqIdcEngCurMax
          ds_EngLim_tqIdcLdMinAdvMin: data-element=P_EngLim_tqIdcLdMinAdvMin.EngLim_tqIdcLdMinAdvMin
          ds_EngLim_tqIdcLdMaxTrbMaxNoOvb: data-element=P_EngLim_tqIdcLdMaxTrbMaxNoOvb.EngLim_tqIdcLdMaxTrbMaxNoOvb
          ds_EngLim_tqIdcPresUsThrMax: data-element=P_EngLim_tqIdcPresUsThrMax.EngLim_tqIdcPresUsThrMax
          ds_EngLim_tqIdcEngCurMinSelc: data-element=P_EngLim_tqIdcEngCurMinSelc.EngLim_tqIdcEngCurMinSelc
          ds_EngLim_tqIdcEngCurMin: data-element=P_EngLim_tqIdcEngCurMin.EngLim_tqIdcEngCurMin
      RE_EngLimTqT_004_DRE: read-variable=[IgSys_tqIdcEstimAvgCyl_irv, IgSys_noCylCutOffDlyOutSat_irv, EngLim_tqIdcPresUsMax_irv, IgSys_tqIdcEstimAvgCylWiLam_irv, EngLim_tqIdcMinAirLd_irv, IgSys_tqIdcEstimAvgCylWoutLa_irv, EngLim_tqIdcTrbMaxWoutOvb_irv, EngLim_tqIdcAdvOptmMaxWoutOf_irv, EngLim_tqIdcMinAirLdAvgCyl_irv], written-variable=[IgSys_tqIdcEstimAvgCyl_irv, EngLim_tqIdcPresUsMax_irv, IgSys_tqIdcEstimAvgCylWiLam_irv, EngLim_tqIdcMinAirLd_irv, IgSys_tqIdcEstimAvgCylWoutLa_irv, EngLim_tqIdcTrbMaxWoutOvb_irv, EngLim_tqIdcAdvOptmMaxWoutOf_irv, EngLim_tqIdcMinAirLdAvgCyl_irv]
        13 x data receive point:
          dr_AirSys_rClcLamEfc: data-element=R_AirSys_rClcLamEfc.AirSys_rClcLamEfc
          dr_EngM_mAirPresUsThr: data-element=R_EngM_mAirPresUsThr.EngM_mAirPresUsThr
          dr_EngLim_tqIdcLimMin: data-element=R_EngLim_tqIdcLimMin.EngLim_tqIdcLimMin
          dr_AirSys_effEGR: data-element=R_AirSys_effEGR.AirSys_effEGR
          dr_IgSys_bAcvStructAir: data-element=R_IgSys_bAcvStructAir.IgSys_bAcvStructAir
          dr_AirSys_effAfr: data-element=R_AirSys_effAfr.AirSys_effAfr
          dr_AirSys_rFullLdLamEfc: data-element=R_AirSys_rFullLdLamEfc.AirSys_rFullLdLamEfc
          dr_EngM_mAirCor: data-element=R_EngM_mAirCor.EngM_mAirCor
          dr_EngM_mAirEngCylMax: data-element=R_EngM_mAirEngCylMax.EngM_mAirEngCylMax
          dr_EngM_mAirEngCylMin: data-element=R_EngM_mAirEngCylMin.EngM_mAirEngCylMin
          dr_EngM_mAirEngCylTrbMax: data-element=R_EngM_mAirEngCylTrbMax.EngM_mAirEngCylTrbMax
          dr_AirSys_effCyc: data-element=R_AirSys_effCyc.AirSys_effCyc
          dr_EV_EngLimTqT_004_DRE: data-element=R_EV_EngLimTqT_004_DRE.EV_EngLimTqT_004_DRE
        data send point ds_EngLim_tqIdcAirTqWoutTotCutOf: data-element=P_EngLim_tqIdcAirTqWoutTotCutOf.EngLim_tqIdcAirTqWoutTotCutOf
        data send point ds_IgSys_tqIdcEstim: data-element=P_IgSys_tqIdcEstim.IgSys_tqIdcEstim
        data send point ds_EngLim_tqIdcAdvOptmTrbMax: data-element=P_EngLim_tqIdcAdvOptmTrbMax.EngLim_tqIdcAdvOptmTrbMax
      RE_EngLimTqT_010_TEV: read-variable=[IgSys_rlamEngCorReq_irv, IgSys_rAirLdPred_irv], written-variable=[IgSys_rlamEngCorReq_irv, IgSys_rAirLdPred_irv]
        7 x data receive point:
          DRP_R_IgSys_rlamClc_IgSys_rlamClc: data-element=R_IgSys_rlamClc.IgSys_rlamClc
          dr_EngM_rAirLdCor: data-element=R_EngM_rAirLdCor.EngM_rAirLdCor
          dr_FARSp_rMixtCylSp: data-element=R_FARSp_rMixtCylSp.FARSp_rMixtCylSp
          dr_EngM_rAirLdPred: data-element=R_EngM_rAirLdPred.EngM_rAirLdPred
          dr_InjSys_bTotCutOff: data-element=R_InjSys_bTotCutOff.InjSys_bTotCutOff
          dr_IgSys_bAcvStructAir: data-element=R_IgSys_bAcvStructAir.IgSys_bAcvStructAir
          dr_IgSys_lamClc: data-element=R_IgSys_lamClc.IgSys_lamClc
        data send point ds_IgSys_rlamClc: data-element=P_IgSys_rlamClc.IgSys_rlamClc
        data send point ds_IgSys_lamClc: data-element=P_IgSys_lamClc.IgSys_lamClc
  swc implementation Imp_EngLimTqT: code-generator=Real-Time Workshop Embedded Coder 5.5 (R2010a) 25-Jan-2010, programming-language=C, behavior=IB_EngLimTqT
    code-descriptors:
      code CodeDescriptor: type=SRC
        10 x xfile:
          EngLimTqT_h: url=EngLimTqT.h
          EngLimTqT_Version_c: url=EngLimTqT_Version.c
          EngLimTqT_Def_c: url=EngLimTqT_Def.c
          EngLimTqT_Version_h: url=EngLimTqT_Version.h
          EngLimTqT_MemMap_h: url=EngLimTqT_MemMap.h
          EngLimTqT_import_h: url=EngLimTqT_import.h
          EngLimTqT_data_c: url=EngLimTqT_data.c
          EngLimTqT_c: url=EngLimTqT.c
          EngLimTqT_types_h: url=EngLimTqT_types.h
          EngLimTqT_private_h: url=EngLimTqT_private.h
package /Components/SWC_EngLimTqT/EngLimTqT_IRVDatatypes
  boolean type DT_IgSys_bTqIdcCutOff_irv: base-type=boolean
  32 x integer type:
    DT_EngLim_tqIdcAdvOptmMaxWoutOf_irv: base-type=int16, lower-limit=-32768, upper-limit=32767
    DT_EngLim_tqIdcMinAirLd_irv: base-type=int16, lower-limit=-32768, upper-limit=32767
    DT_EngLim_tqIdcMinAirLdAvgCyl_irv: base-type=int16, lower-limit=-32768, upper-limit=32767
    DT_EngLim_tqIdcPresUsMax_irv: base-type=int16, lower-limit=-32768, upper-limit=32767
    DT_EngLim_tqIdcTrbMaxWoutOvb_irv: base-type=int16, lower-limit=-32768, upper-limit=32767
    DT_IgSys_noCylCutOffDlyOutSat_irv: base-type=uint8, lower-limit=0, upper-limit=255
    DT_IgSys_noCylInc1_irv: base-type=uint8, lower-limit=0, upper-limit=255
    DT_IgSys_prm_rDynIgSpEfcCyl_{01..06}_irv: base-type=uint16, lower-limit=0, upper-limit=65535
    DT_IgSys_prm_rMaxIgSpEfcCyl_{01..06}_irv: base-type=uint16, lower-limit=0, upper-limit=65535
    DT_IgSys_prm_rStatIgSpEfcCyl_{01..06}_irv: base-type=uint16, lower-limit=0, upper-limit=65535
    DT_IgSys_rAirLdPred_irv: base-type=uint16, lower-limit=0, upper-limit=65535
    DT_IgSys_rDynIgSpEfcWoutMv_irv: base-type=uint16, lower-limit=0, upper-limit=65535
    DT_IgSys_rlamEngCorReq_irv: base-type=uint32, lower-limit=0, upper-limit=4294967295
    DT_IgSys_rStatIgSpEfcWoutMv_irv: base-type=uint16, lower-limit=0, upper-limit=65535
    DT_IgSys_tqIdcEstimAvgCyl_irv: base-type=int16, lower-limit=-32768, upper-limit=32767
    DT_IgSys_tqIdcEstimAvgCylWiLam_irv: base-type=int16, lower-limit=-32768, upper-limit=32767
    DT_IgSys_tqIdcEstimAvgCylWoutLa_irv: base-type=int16, lower-limit=-32768, upper-limit=32767
